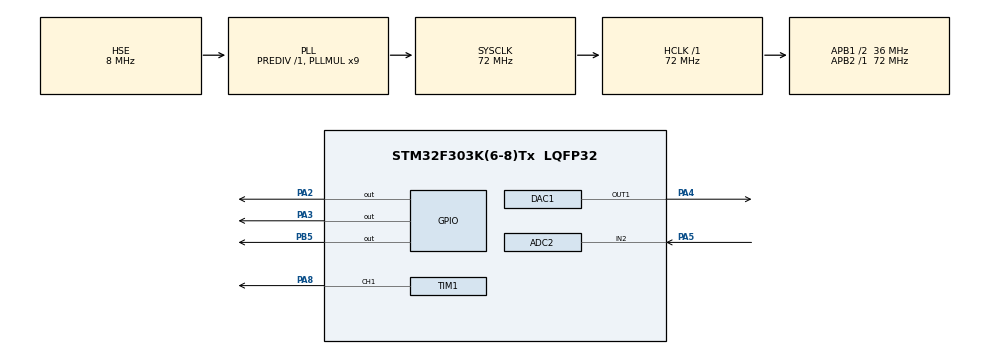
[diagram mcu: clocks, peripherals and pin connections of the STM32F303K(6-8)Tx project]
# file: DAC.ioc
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ADC2.Channel-10\#ChannelRegularConversion=ADC_CHANNEL_2
ADC2.ContinuousConvMode=ENABLE
ADC2.DMAContinuousRequests=ENABLE
ADC2.NbrOfConversionFlag=1
ADC2.Offset-10\#ChannelRegularConversion=0
ADC2.OffsetNumber-10\#ChannelRegularConversion=ADC_OFFSET_NONE
ADC2.Rank-10\#ChannelRegularConversion=1
ADC2.SamplingTime-10\#ChannelRegularConversion=ADC_SAMPLETIME_19CYCLES_5
Dma.ADC2.0.Direction=DMA_PERIPH_TO_MEMORY
Dma.ADC2.0.Instance=DMA1_Channel2
Dma.ADC2.0.MemDataAlignment=DMA_MDATAALIGN_HALFWORD
Dma.ADC2.0.MemInc=DMA_MINC_ENABLE
Dma.ADC2.0.Mode=DMA_CIRCULAR
Dma.ADC2.0.PeriphDataAlignment=DMA_PDATAALIGN_HALFWORD
Dma.ADC2.0.PeriphInc=DMA_PINC_DISABLE
Dma.ADC2.0.Priority=DMA_PRIORITY_LOW
Dma.Request0=ADC2
Mcu.Family=STM32F3
Mcu.Name=STM32F303K(6-8)Tx
Mcu.Package=LQFP32
Mcu.UserConstants=USART_Baudrate,230400;HEDL5540_qPulse,2000;PWM_Period,4096;TIM7_Period,1000;TIM7_Prescaler,7200
NVIC.DMA1_Channel2_IRQn=true\:0\:0\:false\:false\:true
NVIC.PriorityGroup=NVIC_PRIORITYGROUP_0
NVIC.TIM7_DAC2_IRQn=true\:0\:0\:false\:false\:true
PA13.Mode=Serial_Wire
PA13.Signal=SYS_JTMS-SWDIO
PA14.Mode=Serial_Wire
PA14.Signal=SYS_JTCK-SWCLK
PA2.Signal=GPIO_Output
PA3.Signal=GPIO_Output
PA4.Signal=COMP_DAC11_group
PA5.Mode=IN2-Single-Ended
PA5.Signal=ADC2_IN2
PA8.GPIO_PuPd=GPIO_PULLDOWN
PA8.Signal=S_TIM1_CH1
PB5.Signal=GPIO_Output
PF0\ /\ OSC_IN.Mode=HSE-External-Oscillator
PF0\ /\ OSC_IN.Signal=RCC_OSC_IN
PF1\ /\ OSC_OUT.Mode=HSE-External-Oscillator
PF1\ /\ OSC_OUT.Signal=RCC_OSC_OUT
ProjectManager.HeapSize=0x200
ProjectManager.StackSize=0x400
ProjectManager.TargetToolchain=SW4STM32
RCC.AHBFreq_Value=72000000
RCC.APB1CLKDivider=RCC_HCLK_DIV2
RCC.APB1Freq_Value=36000000
RCC.APB1TimFreq_Value=72000000
RCC.APB2Freq_Value=72000000
RCC.APB2TimFreq_Value=72000000
RCC.CortexFreq_Value=72000000
RCC.HCLKFreq_Value=72000000
RCC.HSE_VALUE=8000000
RCC.HSIState=RCC_HSI_ON
RCC.HSI_VALUE=8000000
RCC.PLLMUL=RCC_PLL_MUL9
RCC.PLLSourceVirtual=RCC_PLLSOURCE_HSE
RCC.SYSCLKFreq_VALUE=72000000
RCC.SYSCLKSourceVirtual=RCC_SYSCLKSOURCE_PLLCLK
RCC.Usart1ClockSelection=RCC_USART1CLKSOURCE_SYSCLK
SH.COMP_DAC11_group.0=DAC1_OUT1,DAC_OUT1
SH.S_TIM1_CH1.0=TIM1_CH1,PWM Generation1 CH1
TIM1.CounterMode=TIM_COUNTERMODE_CENTERALIGNED1
TIM1.Period=PWM_Period -1
TIM7.Period=TIM7_Period -1 
TIM7.Prescaler=TIM7_Prescaler -1
VP_TIM7_VS_ClockSourceINT.Mode=Enable_Timer
board=DAC

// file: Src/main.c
/**
  ******************************************************************************
  * File Name          : main.c
  * Description        : Main program body
  ******************************************************************************
  *
  * COPYRIGHT(c) 2017 STMicroelectronics
  *
  * Redistribution and use in source and binary forms, with or without modification,
  * are permitted provided that the following conditions are met:
  *   1. Redistributions of source code must retain the above copyright notice,
  *      this list of conditions and the following disclaimer.
  *   2. Redistributions in binary form must reproduce the above copyright notice,
  *      this list of conditions and the following disclaimer in the documentation
  *      and/or other materials provided with the distribution.
  *   3. Neither the name of STMicroelectronics nor the names of its contributors
  *      may be used to endorse or promote products derived from this software
  *      without specific prior written permission.
  *
  * THIS SOFTWARE IS PROVIDED BY THE COPYRIGHT HOLDERS AND CONTRIBUTORS "AS IS"
  * AND ANY EXPRESS OR IMPLIED WARRANTIES, INCLUDING, BUT NOT LIMITED TO, THE
  * IMPLIED WARRANTIES OF MERCHANTABILITY AND FITNESS FOR A PARTICULAR PURPOSE ARE
  * DISCLAIMED. IN NO EVENT SHALL THE COPYRIGHT HOLDER OR CONTRIBUTORS BE LIABLE
  * FOR ANY DIRECT, INDIRECT, INCIDENTAL, SPECIAL, EXEMPLARY, OR CONSEQUENTIAL
  * DAMAGES (INCLUDING, BUT NOT LIMITED TO, PROCUREMENT OF SUBSTITUTE GOODS OR
  * SERVICES; LOSS OF USE, DATA, OR PROFITS; OR BUSINESS INTERRUPTION) HOWEVER
  * CAUSED AND ON ANY THEORY OF LIABILITY, WHETHER IN CONTRACT, STRICT LIABILITY,
  * OR TORT (INCLUDING NEGLIGENCE OR OTHERWISE) ARISING IN ANY WAY OUT OF THE USE
  * OF THIS SOFTWARE, EVEN IF ADVISED OF THE POSSIBILITY OF SUCH DAMAGE.
  *
  ******************************************************************************
  */
#include "main.h"
#include "stm32f3xx_hal.h"
#include "adc.h"
#include "dac.h"
#include "dma.h"
#include "tim.h"
#include "gpio.h"

/* USER CODE BEGIN PV */
/* Private variables ---------------------------------------------------------*/
enum {ADC_BUFFRT_LENGTH = 10};
uint16_t ADCBuffer[ADC_BUFFRT_LENGTH];
uint32_t ADC_val;
/* USER CODE END PV */

void SystemClock_Config(void);
void Error_Handler(void);

/* USER CODE BEGIN PFP */
/* Private function prototypes -----------------------------------------------*/

/* USER CODE END PFP */

int main(void)
{

  /* MCU Configuration----------------------------------------------------------*/

  /* Reset of all peripherals, Initializes the Flash interface and the Systick. */
  HAL_Init();

  /* Configure the system clock */
  SystemClock_Config();

  /* Initialize all configured peripherals */
  MX_GPIO_Init();
  MX_DMA_Init();
  MX_TIM1_Init();
  MX_ADC2_Init();
  MX_TIM7_Init();
  MX_DAC1_Init();

  /* USER CODE BEGIN 2 */
  uint32_t ADC_tmp;
  HAL_TIM_Base_Start_IT(&htim7);
  HAL_TIM_PWM_Start(&htim1, TIM_CHANNEL_1);
  HAL_DAC_Start(&hdac1, DAC_CHANNEL_1);
  adc_start_cal();
  adc_start(ADCBuffer,ADC_BUFFRT_LENGTH);
  /* USER CODE END 2 */

  /* Infinite loop */
  while (1)
  {
	  HAL_GPIO_TogglePin(GPIOB, GPIO_PIN_5);
	  //HAL_Delay(200);
	  for(uint8_t i = 0 ; i < ADC_BUFFRT_LENGTH ; i++){
	      ADC_tmp = ADC_tmp + ADCBuffer[i];
	      //printf("ADC%d = %d\n",i,ADCBuffer[i]);
	  }
	  ADC_val = (ADC_tmp/ADC_BUFFRT_LENGTH)/16;
	  ADC_tmp = 0;
  }

}

/** System Clock Configuration
*/
void SystemClock_Config(void)
{

  RCC_OscInitTypeDef RCC_OscInitStruct;
  RCC_ClkInitTypeDef RCC_ClkInitStruct;
  RCC_PeriphCLKInitTypeDef PeriphClkInit;

    /**Initializes the CPU, AHB and APB busses clocks
    */
  RCC_OscInitStruct.OscillatorType = RCC_OSCILLATORTYPE_HSE;
  RCC_OscInitStruct.HSEState = RCC_HSE_ON;
  RCC_OscInitStruct.HSEPredivValue = RCC_HSE_PREDIV_DIV1;
  RCC_OscInitStruct.HSIState = RCC_HSI_ON;
  RCC_OscInitStruct.PLL.PLLState = RCC_PLL_ON;
  RCC_OscInitStruct.PLL.PLLSource = RCC_PLLSOURCE_HSE;
  RCC_OscInitStruct.PLL.PLLMUL = RCC_PLL_MUL9;
  if (HAL_RCC_OscConfig(&RCC_OscInitStruct) != HAL_OK)
  {
    Error_Handler();
  }

    /**Initializes the CPU, AHB and APB busses clocks
    */
  RCC_ClkInitStruct.ClockType = RCC_CLOCKTYPE_HCLK|RCC_CLOCKTYPE_SYSCLK
                              |RCC_CLOCKTYPE_PCLK1|RCC_CLOCKTYPE_PCLK2;
  RCC_ClkInitStruct.SYSCLKSource = RCC_SYSCLKSOURCE_PLLCLK;
  RCC_ClkInitStruct.AHBCLKDivider = RCC_SYSCLK_DIV1;
  RCC_ClkInitStruct.APB1CLKDivider = RCC_HCLK_DIV2;
  RCC_ClkInitStruct.APB2CLKDivider = RCC_HCLK_DIV1;

  if (HAL_RCC_ClockConfig(&RCC_ClkInitStruct, FLASH_LATENCY_2) != HAL_OK)
  {
    Error_Handler();
  }

  PeriphClkInit.PeriphClockSelection = RCC_PERIPHCLK_TIM1|RCC_PERIPHCLK_ADC12;
  PeriphClkInit.Adc12ClockSelection = RCC_ADC12PLLCLK_DIV1;
  PeriphClkInit.Tim1ClockSelection = RCC_TIM1CLK_HCLK;
  if (HAL_RCCEx_PeriphCLKConfig(&PeriphClkInit) != HAL_OK)
  {
    Error_Handler();
  }

    /**Configure the Systick interrupt time
    */
  HAL_SYSTICK_Config(HAL_RCC_GetHCLKFreq()/1000);

    /**Configure the Systick
    */
  HAL_SYSTICK_CLKSourceConfig(SYSTICK_CLKSOURCE_HCLK);

  /* SysTick_IRQn interrupt configuration */
  HAL_NVIC_SetPriority(SysTick_IRQn, 0, 0);
}

void Error_Handler(void)
{
  while(1)
  {
  }
}

/************************ (C) COPYRIGHT STMicroelectronics *****END OF FILE****/
